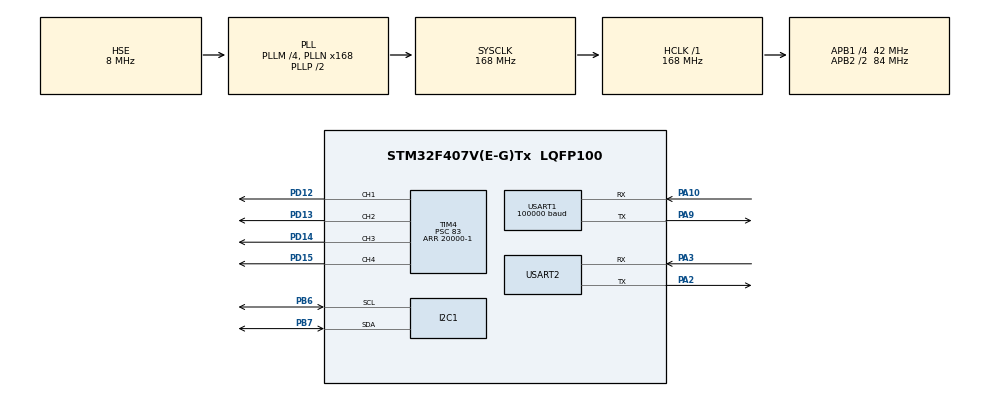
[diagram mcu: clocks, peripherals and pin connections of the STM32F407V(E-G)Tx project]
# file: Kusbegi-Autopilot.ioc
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Dma.Request0=USART1_RX
Dma.USART1_RX.0.Direction=DMA_PERIPH_TO_MEMORY
Dma.USART1_RX.0.FIFOMode=DMA_FIFOMODE_DISABLE
Dma.USART1_RX.0.Instance=DMA2_Stream2
Dma.USART1_RX.0.MemDataAlignment=DMA_MDATAALIGN_BYTE
Dma.USART1_RX.0.MemInc=DMA_MINC_ENABLE
Dma.USART1_RX.0.Mode=DMA_NORMAL
Dma.USART1_RX.0.PeriphDataAlignment=DMA_PDATAALIGN_BYTE
Dma.USART1_RX.0.PeriphInc=DMA_PINC_DISABLE
Dma.USART1_RX.0.Priority=DMA_PRIORITY_MEDIUM
I2C1.DutyCycle=I2C_DUTYCYCLE_16_9
I2C1.I2C_Mode=I2C_Fast
Mcu.Family=STM32F4
Mcu.Name=STM32F407V(E-G)Tx
Mcu.Package=LQFP100
NVIC.DMA2_Stream2_IRQn=true\:0\:0\:false\:false\:true\:false\:true
NVIC.PriorityGroup=NVIC_PRIORITYGROUP_4
NVIC.USART2_IRQn=true\:0\:0\:false\:false\:true\:true\:true
PA10.Mode=Asynchronous
PA10.Signal=USART1_RX
PA13.Mode=Serial_Wire
PA13.Signal=SYS_JTMS-SWDIO
PA14.Mode=Serial_Wire
PA14.Signal=SYS_JTCK-SWCLK
PA2.Mode=Asynchronous
PA2.Signal=USART2_TX
PA3.Mode=Asynchronous
PA3.Signal=USART2_RX
PA9.Mode=Asynchronous
PA9.Signal=USART1_TX
PB6.Mode=I2C
PB6.Signal=I2C1_SCL
PB7.Mode=I2C
PB7.Signal=I2C1_SDA
PD12.Signal=S_TIM4_CH1
PD13.Signal=S_TIM4_CH2
PD14.Signal=S_TIM4_CH3
PD15.Signal=S_TIM4_CH4
PH0-OSC_IN.Mode=HSE-External-Oscillator
PH0-OSC_IN.Signal=RCC_OSC_IN
PH1-OSC_OUT.Mode=HSE-External-Oscillator
PH1-OSC_OUT.Signal=RCC_OSC_OUT
ProjectManager.HeapSize=0x200
ProjectManager.StackSize=0x400
ProjectManager.TargetToolchain=STM32CubeIDE
RCC.48MHZClocksFreq_Value=84000000
RCC.AHBFreq_Value=168000000
RCC.APB1CLKDivider=RCC_HCLK_DIV4
RCC.APB1Freq_Value=42000000
RCC.APB1TimFreq_Value=84000000
RCC.APB2CLKDivider=RCC_HCLK_DIV2
RCC.APB2Freq_Value=84000000
RCC.APB2TimFreq_Value=168000000
RCC.CortexFreq_Value=168000000
RCC.HCLKFreq_Value=168000000
RCC.HSE_VALUE=8000000
RCC.HSI_VALUE=16000000
RCC.LSE_VALUE=32768
RCC.PLLM=4
RCC.PLLN=168
RCC.PLLSourceVirtual=RCC_PLLSOURCE_HSE
RCC.SYSCLKFreq_VALUE=168000000
RCC.SYSCLKSource=RCC_SYSCLKSOURCE_PLLCLK
RCC.VCOOutputFreq_Value=336000000
SH.S_TIM4_CH1.0=TIM4_CH1,PWM Generation1 CH1
SH.S_TIM4_CH2.0=TIM4_CH2,PWM Generation2 CH2
SH.S_TIM4_CH3.0=TIM4_CH3,PWM Generation3 CH3
SH.S_TIM4_CH4.0=TIM4_CH4,PWM Generation4 CH4
TIM4.Channel-PWM\ Generation1\ CH1=TIM_CHANNEL_1
TIM4.Channel-PWM\ Generation2\ CH2=TIM_CHANNEL_2
TIM4.Channel-PWM\ Generation3\ CH3=TIM_CHANNEL_3
TIM4.Channel-PWM\ Generation4\ CH4=TIM_CHANNEL_4
TIM4.Period=20000-1
TIM4.Prescaler=83
USART1.BaudRate=100000
USART1.StopBits=STOPBITS_2
USART1.VirtualMode=VM_ASYNC
USART2.VirtualMode=VM_ASYNC
board=custom

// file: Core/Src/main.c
/* USER CODE BEGIN Header */
/**
  ******************************************************************************
  * @file           : main.c
  * @brief          : Main program body
  ******************************************************************************
  * @attention
  *
  * <h2><center>&copy; Copyright (c) 2020 STMicroelectronics.
  * All rights reserved.</center></h2>
  *
  * This software component is licensed by ST under BSD 3-Clause license,
  * the "License"; You may not use this file except in compliance with the
  * License. You may obtain a copy of the License at:
  *                        opensource.org/licenses/BSD-3-Clause
  *
  ******************************************************************************
  */
/* USER CODE END Header */
#include "main.h"

I2C_HandleTypeDef hi2c1;

TIM_HandleTypeDef htim4;

UART_HandleTypeDef huart1;
UART_HandleTypeDef huart2;
DMA_HandleTypeDef hdma_usart1_rx;

void SystemClock_Config(void);
static void MX_GPIO_Init(void);
static void MX_DMA_Init(void);
static void MX_I2C1_Init(void);
static void MX_TIM4_Init(void);
static void MX_USART1_UART_Init(void);
static void MX_USART2_UART_Init(void);

int main(void)
{

  /* MCU Configuration--------------------------------------------------------*/

  /* Reset of all peripherals, Initializes the Flash interface and the Systick. */
  HAL_Init();

  /* Configure the system clock */
  SystemClock_Config();

  /* Initialize all configured peripherals */
  MX_GPIO_Init();
  MX_DMA_Init();
  MX_I2C1_Init();
  MX_TIM4_Init();
  MX_USART1_UART_Init();
  MX_USART2_UART_Init();
  /* USER CODE BEGIN 2 */
	HAL_TIM_PWM_Start(&htim4, TIM_CHANNEL_1);
	HAL_TIM_PWM_Start(&htim4, TIM_CHANNEL_2);
	HAL_TIM_PWM_Start(&htim4, TIM_CHANNEL_3);
	HAL_TIM_PWM_Start(&htim4, TIM_CHANNEL_4);

	KUSBEGI kusbegi;

	sendString("init:", &huart2, 1);
	sendInt(kusbegi_init(&huart2, &hi2c1, &huart1, &kusbegi), &huart2, 1);

  /* USER CODE END 2 */

  /* Infinite loop */
  /* USER CODE BEGIN WHILE */
  while (1)
  {

	  	if(debugger_flag != -1){
		kusbegi_loop(&huart2, &hi2c1, &huart1, &kusbegi);
	  	}

		TIM4->CCR1 = kusbegi.PWM_US_MOTOR[0];
		TIM4->CCR2 = kusbegi.PWM_US_MOTOR[1];
		TIM4->CCR3 = kusbegi.PWM_US_MOTOR[2];
		TIM4->CCR4 = kusbegi.PWM_US_MOTOR[3];

    /* USER CODE END WHILE */

  }
}

void SystemClock_Config(void)
{
  RCC_OscInitTypeDef RCC_OscInitStruct = {0};
  RCC_ClkInitTypeDef RCC_ClkInitStruct = {0};

  /** Configure the main internal regulator output voltage
  */
  __HAL_RCC_PWR_CLK_ENABLE();
  __HAL_PWR_VOLTAGESCALING_CONFIG(PWR_REGULATOR_VOLTAGE_SCALE1);
  /** Initializes the RCC Oscillators according to the specified parameters
  * in the RCC_OscInitTypeDef structure.
  */
  RCC_OscInitStruct.OscillatorType = RCC_OSCILLATORTYPE_HSE;
  RCC_OscInitStruct.HSEState = RCC_HSE_ON;
  RCC_OscInitStruct.PLL.PLLState = RCC_PLL_ON;
  RCC_OscInitStruct.PLL.PLLSource = RCC_PLLSOURCE_HSE;
  RCC_OscInitStruct.PLL.PLLM = 4;
  RCC_OscInitStruct.PLL.PLLN = 168;
  RCC_OscInitStruct.PLL.PLLP = RCC_PLLP_DIV2;
  RCC_OscInitStruct.PLL.PLLQ = 4;
  if (HAL_RCC_OscConfig(&RCC_OscInitStruct) != HAL_OK)
  {
    Error_Handler();
  }
  /** Initializes the CPU, AHB and APB buses clocks
  */
  RCC_ClkInitStruct.ClockType = RCC_CLOCKTYPE_HCLK|RCC_CLOCKTYPE_SYSCLK
                              |RCC_CLOCKTYPE_PCLK1|RCC_CLOCKTYPE_PCLK2;
  RCC_ClkInitStruct.SYSCLKSource = RCC_SYSCLKSOURCE_PLLCLK;
  RCC_ClkInitStruct.AHBCLKDivider = RCC_SYSCLK_DIV1;
  RCC_ClkInitStruct.APB1CLKDivider = RCC_HCLK_DIV4;
  RCC_ClkInitStruct.APB2CLKDivider = RCC_HCLK_DIV2;

  if (HAL_RCC_ClockConfig(&RCC_ClkInitStruct, FLASH_LATENCY_5) != HAL_OK)
  {
    Error_Handler();
  }
}

static void MX_I2C1_Init(void)
{

  hi2c1.Instance = I2C1;
  hi2c1.Init.ClockSpeed = 400000;
  hi2c1.Init.DutyCycle = I2C_DUTYCYCLE_16_9;
  hi2c1.Init.OwnAddress1 = 0;
  hi2c1.Init.AddressingMode = I2C_ADDRESSINGMODE_7BIT;
  hi2c1.Init.DualAddressMode = I2C_DUALADDRESS_DISABLE;
  hi2c1.Init.OwnAddress2 = 0;
  hi2c1.Init.GeneralCallMode = I2C_GENERALCALL_DISABLE;
  hi2c1.Init.NoStretchMode = I2C_NOSTRETCH_DISABLE;
  if (HAL_I2C_Init(&hi2c1) != HAL_OK)
  {
    Error_Handler();
  }

}

static void MX_TIM4_Init(void)
{

  TIM_MasterConfigTypeDef sMasterConfig = {0};
  TIM_OC_InitTypeDef sConfigOC = {0};

  htim4.Instance = TIM4;
  htim4.Init.Prescaler = 83;
  htim4.Init.CounterMode = TIM_COUNTERMODE_UP;
  htim4.Init.Period = 20000-1;
  htim4.Init.ClockDivision = TIM_CLOCKDIVISION_DIV1;
  htim4.Init.AutoReloadPreload = TIM_AUTORELOAD_PRELOAD_DISABLE;
  if (HAL_TIM_PWM_Init(&htim4) != HAL_OK)
  {
    Error_Handler();
  }
  sMasterConfig.MasterOutputTrigger = TIM_TRGO_RESET;
  sMasterConfig.MasterSlaveMode = TIM_MASTERSLAVEMODE_DISABLE;
  if (HAL_TIMEx_MasterConfigSynchronization(&htim4, &sMasterConfig) != HAL_OK)
  {
    Error_Handler();
  }
  sConfigOC.OCMode = TIM_OCMODE_PWM1;
  sConfigOC.Pulse = 0;
  sConfigOC.OCPolarity = TIM_OCPOLARITY_HIGH;
  sConfigOC.OCFastMode = TIM_OCFAST_DISABLE;
  if (HAL_TIM_PWM_ConfigChannel(&htim4, &sConfigOC, TIM_CHANNEL_1) != HAL_OK)
  {
    Error_Handler();
  }
  if (HAL_TIM_PWM_ConfigChannel(&htim4, &sConfigOC, TIM_CHANNEL_2) != HAL_OK)
  {
    Error_Handler();
  }
  if (HAL_TIM_PWM_ConfigChannel(&htim4, &sConfigOC, TIM_CHANNEL_3) != HAL_OK)
  {
    Error_Handler();
  }
  if (HAL_TIM_PWM_ConfigChannel(&htim4, &sConfigOC, TIM_CHANNEL_4) != HAL_OK)
  {
    Error_Handler();
  }
  HAL_TIM_MspPostInit(&htim4);

}

static void MX_USART1_UART_Init(void)
{

  huart1.Instance = USART1;
  huart1.Init.BaudRate = 100000;
  huart1.Init.WordLength = UART_WORDLENGTH_8B;
  huart1.Init.StopBits = UART_STOPBITS_2;
  huart1.Init.Parity = UART_PARITY_NONE;
  huart1.Init.Mode = UART_MODE_TX_RX;
  huart1.Init.HwFlowCtl = UART_HWCONTROL_NONE;
  huart1.Init.OverSampling = UART_OVERSAMPLING_16;
  if (HAL_UART_Init(&huart1) != HAL_OK)
  {
    Error_Handler();
  }

}

static void MX_USART2_UART_Init(void)
{

  huart2.Instance = USART2;
  huart2.Init.BaudRate = 115200;
  huart2.Init.WordLength = UART_WORDLENGTH_8B;
  huart2.Init.StopBits = UART_STOPBITS_1;
  huart2.Init.Parity = UART_PARITY_NONE;
  huart2.Init.Mode = UART_MODE_TX_RX;
  huart2.Init.HwFlowCtl = UART_HWCONTROL_NONE;
  huart2.Init.OverSampling = UART_OVERSAMPLING_16;
  if (HAL_UART_Init(&huart2) != HAL_OK)
  {
    Error_Handler();
  }

}

static void MX_DMA_Init(void)
{

  /* DMA controller clock enable */
  __HAL_RCC_DMA2_CLK_ENABLE();

  /* DMA interrupt init */
  /* DMA2_Stream2_IRQn interrupt configuration */
  HAL_NVIC_SetPriority(DMA2_Stream2_IRQn, 0, 0);
  HAL_NVIC_EnableIRQ(DMA2_Stream2_IRQn);

}

static void MX_GPIO_Init(void)
{

  /* GPIO Ports Clock Enable */
  __HAL_RCC_GPIOH_CLK_ENABLE();
  __HAL_RCC_GPIOA_CLK_ENABLE();
  __HAL_RCC_GPIOD_CLK_ENABLE();
  __HAL_RCC_GPIOB_CLK_ENABLE();

}

void Error_Handler(void)
{
}

/************************ (C) COPYRIGHT STMicroelectronics *****END OF FILE****/
